# wiz16b8m4ct3_0_WIZ16B8M4CT3 register map
Vendor: Texas Instruments
Registers are 32-bit, read-write, reset 0x0 unless marked. A register's access mark holds for its fields unless they carry their own. Offsets are as the file gives them; [hi:lo] are bit positions.

## wiz16b8m4ct3_0_WIZ16B8M4CT3 (part 10 of 12)
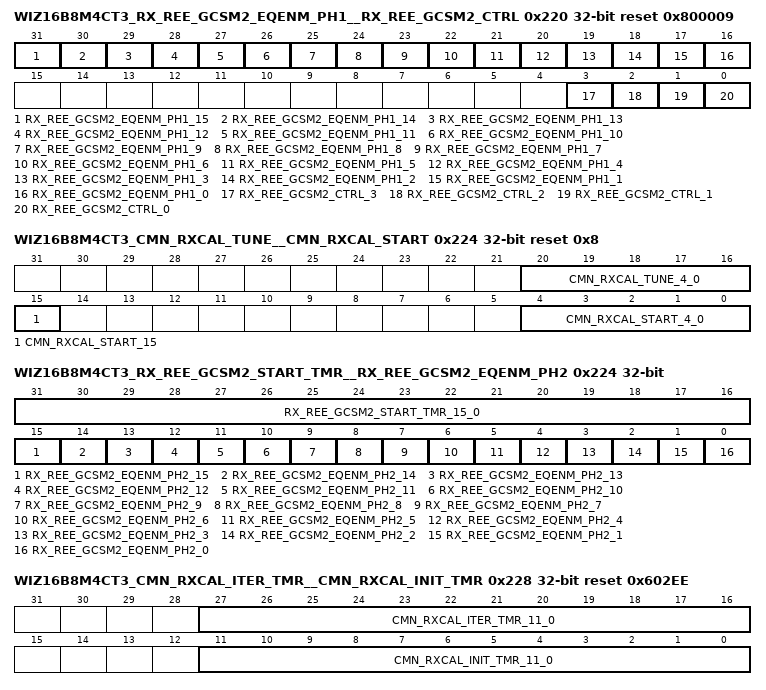
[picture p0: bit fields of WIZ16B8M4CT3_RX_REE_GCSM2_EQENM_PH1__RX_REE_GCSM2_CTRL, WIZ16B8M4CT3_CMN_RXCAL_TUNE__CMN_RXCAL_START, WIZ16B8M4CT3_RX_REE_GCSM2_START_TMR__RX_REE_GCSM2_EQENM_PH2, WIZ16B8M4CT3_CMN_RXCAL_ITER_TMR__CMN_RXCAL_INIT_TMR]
0x220 WIZ16B8M4CT3_RX_REE_GCSM2_EQENM_PH1__RX_REE_GCSM2_CTRL reset 0x800009
  [31] RX_REE_GCSM2_EQENM_PH1_15 — Reserved - spare
  [30] RX_REE_GCSM2_EQENM_PH1_14 — Ignore 1010 controller : When set to 1'b1, this function is enabled when the general control state machine 2 is controlling the REE.
  [29] RX_REE_GCSM2_EQENM_PH1_13 — TX equalization evaluator : When set to 1'b1, this function is enabled when the general control state machine 2 is controlling the REE.
  [28] RX_REE_GCSM2_EQENM_PH1_12 — TX post cursor control : When set to 1'b1, this function is enabled when the general control state machine 2 is controlling the REE.
  [27] RX_REE_GCSM2_EQENM_PH1_11 — TX pre cursor control : When set to 1'b1, this function is enabled when the general control state machine 2 is controlling the REE.
  [26] RX_REE_GCSM2_EQENM_PH1_10 — Short channel correction : When set to 1'b1, this function is enabled when the general control state machine 2 is controlling the REE.
  [25] RX_REE_GCSM2_EQENM_PH1_9 — RX attenuation : When set to 1'b1, this function is enabled when the general control state machine 2 is controlling the REE.
  [24] RX_REE_GCSM2_EQENM_PH1_8 — RX VGA gain : When set to 1'b1, this function is enabled when the general control state machine 2 is controlling the REE.
  [23] RX_REE_GCSM2_EQENM_PH1_7 — RX offset correction coefficient : When set to 1'b1, this function is enabled when the general control state machine 2 is controlling the REE.
  [22] RX_REE_GCSM2_EQENM_PH1_6 — RX peaking amp gain : When set to 1'b1, this function is enabled when the general control state machine 2 is controlling the REE.
  [21] RX_REE_GCSM2_EQENM_PH1_5 — RX low frequency equalizer adaptive control : When set to 1'b1, this function is enabled when the general control state machine 2 is controlling the REE.
  [20] RX_REE_GCSM2_EQENM_PH1_4 — Reserved - spare
  [19] RX_REE_GCSM2_EQENM_PH1_3 — Reserved - spare
  [18] RX_REE_GCSM2_EQENM_PH1_2 — RX tap 3 : When set to 1'b1, this function is enabled when the general control state machine 2 is controlling the REE.
  [17] RX_REE_GCSM2_EQENM_PH1_1 — RX tap 2 : When set to 1'b1, this function is enabled when the general control state machine 2 is controlling the REE.
  [16] RX_REE_GCSM2_EQENM_PH1_0 — RX tap 1 : When set to 1'b1, this function is enabled when the general control state machine 2 is controlling the REE.
  [3] RX_REE_GCSM2_CTRL_3 — Equalization function reset enable: Enables the reset of the functions controlled by this state machine, using the rx_ree_fcn_reset_n signal, when the equalization mode changes. 1'b1 : Enabled 1'b0 : Disabled
  [2] RX_REE_GCSM2_CTRL_2 — Loop enable: Controls when the equalization functions in this state machine are run one time or loop continuously.
  [1] RX_REE_GCSM2_CTRL_1 — Force run equalization: Setting this bit to a 1'b1, will force the general control state machine to run, independent of the macro functions that normally run the equalization.
  [0] RX_REE_GCSM2_CTRL_0 — Enable: This bit enables the general control state machine function. 1'b1 : Enabled 1'b0 : Disabled
0x224 WIZ16B8M4CT3_CMN_RXCAL_TUNE__CMN_RXCAL_START reset 0x8
  [20:16] CMN_RXCAL_TUNE_4_0 — Resistor calibration tune value: The value of this field is added to the automatically calibrated code, or the override code if override is enabled. Note: This value is a twos complement value, so the calibrated code can be increased or decreased.
  [15] CMN_RXCAL_START_15 — Resistor calibration direction: This controls the direction that the automatic calibration process steps the calibration codes in. 1'b0 : From 4'b0000 to 4'b0111. 1'b1 : From 4'b0111 to 4'b0000.
  [4:0] CMN_RXCAL_START_4_0 — Start resistor calibration code: This is the calibration code that the resistor calibration process starts with when automatic calibration is run. The following are the values for the code. 5'b00000: No resistors active 5'b00001: 1 resistor active 5'b00010: 2 resistors active 5'b00011: 3 resistors active ... 5'b01110: 14 resistors active. 5'b01111: 15 resistors active. Note: The most significant bit is the calibration code sign bit, and is always 1'b0 in this application.
0x224 WIZ16B8M4CT3_RX_REE_GCSM2_START_TMR__RX_REE_GCSM2_EQENM_PH2
  [31:16] RX_REE_GCSM2_START_TMR_15_0 — Start timer value : The number of clock cycles the state machine will wait in the Start Delay state. Note: This value is shifted left 8 bits when loading the timer, the actual time is 256X this value.
  [15] RX_REE_GCSM2_EQENM_PH2_15 — Reserved - spare
  [14] RX_REE_GCSM2_EQENM_PH2_14 — Ignore 1010 controller : When set to 1'b1, this function is enabled when the general control state machine 2 is controlling the REE.
  [13] RX_REE_GCSM2_EQENM_PH2_13 — TX equalization evaluator : When set to 1'b1, this function is enabled when the general control state machine 2 is controlling the REE.
  [12] RX_REE_GCSM2_EQENM_PH2_12 — TX post cursor control : When set to 1'b1, this function is enabled when the general control state machine 2 is controlling the REE.
  [11] RX_REE_GCSM2_EQENM_PH2_11 — TX pre cursor control : When set to 1'b1, this function is enabled when the general control state machine 2 is controlling the REE.
  [10] RX_REE_GCSM2_EQENM_PH2_10 — Short channel correction : When set to 1'b1, this function is enabled when the general control state machine 2 is controlling the REE.
  [9] RX_REE_GCSM2_EQENM_PH2_9 — RX attenuation : When set to 1'b1, this function is enabled when the general control state machine 2 is controlling the REE.
  [8] RX_REE_GCSM2_EQENM_PH2_8 — RX VGA gain : When set to 1'b1, this function is enabled when the general control state machine 2 is controlling the REE.
  [7] RX_REE_GCSM2_EQENM_PH2_7 — RX offset correction coefficient : When set to 1'b1, this function is enabled when the general control state machine 2 is controlling the REE.
  [6] RX_REE_GCSM2_EQENM_PH2_6 — RX peaking amp gain : When set to 1'b1, this function is enabled when the general control state machine 2 is controlling the REE.
  [5] RX_REE_GCSM2_EQENM_PH2_5 — RX low frequency equalizer adaptive control : When set to 1'b1, this function is enabled when the general control state machine 2 is controlling the REE.
  [4] RX_REE_GCSM2_EQENM_PH2_4 — Reserved - spare
  [3] RX_REE_GCSM2_EQENM_PH2_3 — Reserved - spare
  [2] RX_REE_GCSM2_EQENM_PH2_2 — RX tap 3 : When set to 1'b1, this function is enabled when the general control state machine 2 is controlling the REE.
  [1] RX_REE_GCSM2_EQENM_PH2_1 — RX tap 2 : When set to 1'b1, this function is enabled when the general control state machine 2 is controlling the REE.
  [0] RX_REE_GCSM2_EQENM_PH2_0 — RX tap 1 : When set to 1'b1, this function is enabled when the general control state machine 2 is controlling the REE.
0x228 WIZ16B8M4CT3_CMN_RXCAL_ITER_TMR__CMN_RXCAL_INIT_TMR reset 0x602EE
  [27:16] CMN_RXCAL_ITER_TMR_11_0 — Iteration wait timer value: This is the number of cmn_ref_clk clocks to wait between when a value is placed on the resistor selection bus going to the analog, and when the comparator value coming from the analog circuits can be checked. Note: This results in the minimum number of cmn_ref_clk clocks required to wait 240 nSec. Note: This should never be set to a value of less than 3.
  [11:0] CMN_RXCAL_INIT_TMR_11_0 — Initialization wait timer value: This is the number of cmn_ref_clk clocks to wait between when the analog resistor calibration circuits are enabled, and when the first resistor selection values are placed on the resistor selection bus, going to the analog. Note: This results in the minimum number of cmn_ref_clk clocks required to wait 30 uSec. Note: This should never be set to a value of less than 1.
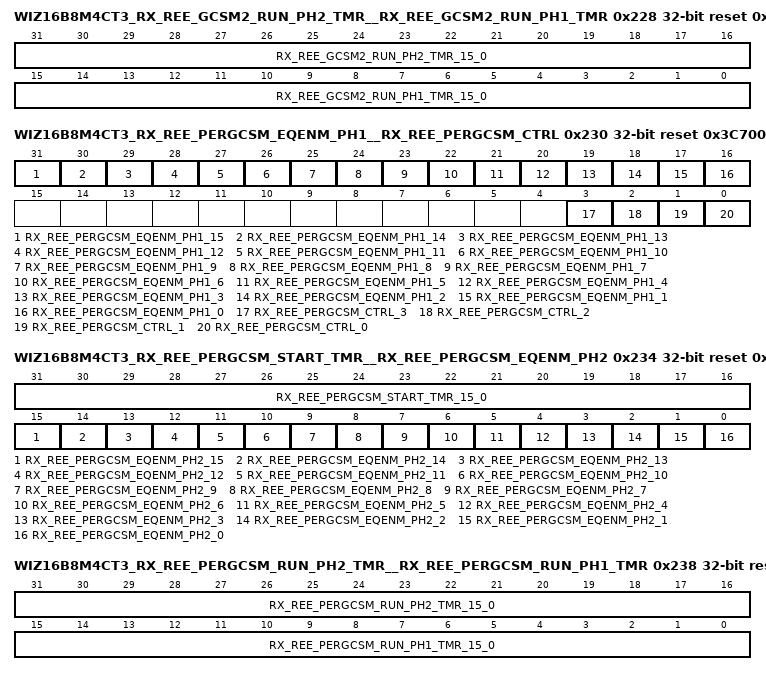
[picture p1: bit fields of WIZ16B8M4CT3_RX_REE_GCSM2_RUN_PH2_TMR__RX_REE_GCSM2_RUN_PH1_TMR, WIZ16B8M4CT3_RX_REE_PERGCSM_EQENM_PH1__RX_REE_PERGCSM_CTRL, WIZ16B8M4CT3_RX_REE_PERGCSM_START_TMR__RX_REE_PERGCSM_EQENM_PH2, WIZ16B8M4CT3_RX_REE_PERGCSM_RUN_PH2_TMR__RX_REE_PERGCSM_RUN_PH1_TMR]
0x228 WIZ16B8M4CT3_RX_REE_GCSM2_RUN_PH2_TMR__RX_REE_GCSM2_RUN_PH1_TMR reset 0xFFFF
  [31:16] RX_REE_GCSM2_RUN_PH2_TMR_15_0 — Run phase 2 timer value : This specifies the number of clock cycles the state machine will wait in the Run Equalization Phase 2 state. Note: This value is shifted left 8 bits when loading the timer, the actual time is 256X this value.
  [15:0] RX_REE_GCSM2_RUN_PH1_TMR_15_0 — Run phase 1 timer value : This specifies the number of clock cycles the state machine will wait in the Run Equalization Phase 1 state. If this register is set to all 1s, the run in the Run Equalization Phase 1 state indefinitely. Note: This value is shifted left 8 bits when loading the timer, the actual time is 256X this value.
0x230 WIZ16B8M4CT3_RX_REE_PERGCSM_EQENM_PH1__RX_REE_PERGCSM_CTRL reset 0x3C7000D
  [31] RX_REE_PERGCSM_EQENM_PH1_15 — Reserved - spare
  [30] RX_REE_PERGCSM_EQENM_PH1_14 — Ignore 1010 controller : When set to 1'b1, this function is enabled when the periodic general control state machine is controlling the REE.
  [29] RX_REE_PERGCSM_EQENM_PH1_13 — TX equalization evaluator : When set to 1'b1, this function is enabled when the periodic general control state machine is controlling the REE.
  [28] RX_REE_PERGCSM_EQENM_PH1_12 — TX post cursor control : When set to 1'b1, this function is enabled when the periodic general control state machine is controlling the REE.
  [27] RX_REE_PERGCSM_EQENM_PH1_11 — TX pre cursor control : When set to 1'b1, this function is enabled when the periodic general control state machine is controlling the REE.
  [26] RX_REE_PERGCSM_EQENM_PH1_10 — Short channel correction : When set to 1'b1, this function is enabled when the periodic general control state machine is controlling the REE.
  [25] RX_REE_PERGCSM_EQENM_PH1_9 — RX attenuation : When set to 1'b1, this function is enabled when the periodic general control state machine is controlling the REE.
  [24] RX_REE_PERGCSM_EQENM_PH1_8 — RX VGA gain : When set to 1'b1, this function is enabled when the periodic general control state machine is controlling the REE.
  [23] RX_REE_PERGCSM_EQENM_PH1_7 — RX offset correction coefficient : When set to 1'b1, this function is enabled when the periodic general control state machine is controlling the REE.
  [22] RX_REE_PERGCSM_EQENM_PH1_6 — RX peaking amp gain : When set to 1'b1, this function is enabled when the periodic general control state machine is controlling the REE.
  [21] RX_REE_PERGCSM_EQENM_PH1_5 — RX low frequency equalizer adaptive control : When set to 1'b1, this function is enabled when the periodic general control state machine is controlling the REE.
  [20] RX_REE_PERGCSM_EQENM_PH1_4 — Reserved - spare
  [19] RX_REE_PERGCSM_EQENM_PH1_3 — Reserved - spare
  [18] RX_REE_PERGCSM_EQENM_PH1_2 — RX tap 3 : When set to 1'b1, this function is enabled when the periodic general control state machine is controlling the REE.
  [17] RX_REE_PERGCSM_EQENM_PH1_1 — RX tap 2 : When set to 1'b1, this function is enabled when the periodic general control state machine is controlling the REE.
  [16] RX_REE_PERGCSM_EQENM_PH1_0 — RX tap 1 : When set to 1'b1, this function is enabled when the periodic general control state machine is controlling the REE.
  [3] RX_REE_PERGCSM_CTRL_3 — Equalization function reset enable: Enables the reset of the functions controlled by this state machine, using the rx_ree_fcn_reset_n pin, when the equalization mode changes. 1'b1 : Enabled 1'b0 : Disabled
  [2] RX_REE_PERGCSM_CTRL_2 — Loop enable: Controls when the equalization functions in this state machine are run one time or loop continuously.
  [1] RX_REE_PERGCSM_CTRL_1 — Force run equalization: Setting this bit to a 1'b1, will force the general control state machine to run, independent of the macro functions that normally run the equalization.
  [0] RX_REE_PERGCSM_CTRL_0 — Enable: This bit enables the general control state machine function. 1'b1 : Enabled 1'b0 : Disabled
0x234 WIZ16B8M4CT3_RX_REE_PERGCSM_START_TMR__RX_REE_PERGCSM_EQENM_PH2 reset 0x1E8501C7
  [31:16] RX_REE_PERGCSM_START_TMR_15_0 — Start timer value : The number of clock cycles the state machine will wait in the Start Delay state. Note: This value is shifted left 8 bits when loading the timer, the actual time is 256X this value.
  [15] RX_REE_PERGCSM_EQENM_PH2_15 — Reserved - spare
  [14] RX_REE_PERGCSM_EQENM_PH2_14 — Ignore 1010 controller : When set to 1'b1, this function is enabled when the periodic general control state machine is controlling the REE.
  [13] RX_REE_PERGCSM_EQENM_PH2_13 — TX equalization evaluator : When set to 1'b1, this function is enabled when the periodic general control state machine is controlling the REE.
  [12] RX_REE_PERGCSM_EQENM_PH2_12 — TX post cursor control : When set to 1'b1, this function is enabled when the periodic general control state machine is controlling the REE.
  [11] RX_REE_PERGCSM_EQENM_PH2_11 — TX pre cursor control : When set to 1'b1, this function is enabled when the periodic general control state machine is controlling the REE.
  [10] RX_REE_PERGCSM_EQENM_PH2_10 — Short channel correction : When set to 1'b1, this function is enabled when the periodic general control state machine is controlling the REE.
  [9] RX_REE_PERGCSM_EQENM_PH2_9 — RX attenuation : When set to 1'b1, this function is enabled when the periodic general control state machine is controlling the REE.
  [8] RX_REE_PERGCSM_EQENM_PH2_8 — RX VGA gain : When set to 1'b1, this function is enabled when the periodic general control state machine is controlling the REE.
  [7] RX_REE_PERGCSM_EQENM_PH2_7 — RX offset correction coefficient : When set to 1'b1, this function is enabled when the periodic general control state machine is controlling the REE.
  [6] RX_REE_PERGCSM_EQENM_PH2_6 — RX peaking amp gain : When set to 1'b1, this function is enabled when the periodic general control state machine is controlling the REE.
  [5] RX_REE_PERGCSM_EQENM_PH2_5 — RX low frequency equalizer adaptive control : When set to 1'b1, this function is enabled when the periodic general control state machine is controlling the REE.
  [4] RX_REE_PERGCSM_EQENM_PH2_4 — Reserved - spare
  [3] RX_REE_PERGCSM_EQENM_PH2_3 — Reserved - spare
  [2] RX_REE_PERGCSM_EQENM_PH2_2 — RX tap 3 : When set to 1'b1, this function is enabled when the periodic general control state machine is controlling the REE.
  [1] RX_REE_PERGCSM_EQENM_PH2_1 — RX tap 2 : When set to 1'b1, this function is enabled when the periodic general control state machine is controlling the REE.
  [0] RX_REE_PERGCSM_EQENM_PH2_0 — RX tap 1 : When set to 1'b1, this function is enabled when the periodic general control state machine is controlling the REE.
0x238 WIZ16B8M4CT3_RX_REE_PERGCSM_RUN_PH2_TMR__RX_REE_PERGCSM_RUN_PH1_TMR reset 0x9D009D
  [31:16] RX_REE_PERGCSM_RUN_PH2_TMR_15_0 — Run phase 2 timer value : This specifies the number of clock cycles the state machine will wait in the Run Equalization Phase 2 state. Note: This value is shifted left 8 bits when loading the timer, the actual time is 256X this value.
  [15:0] RX_REE_PERGCSM_RUN_PH1_TMR_15_0 — Run phase 1 timer value : This specifies the number of clock cycles the state machine will wait in the Run Equalization Phase 1 state. If this register is set to all 1s, the run in the Run Equalization Phase 1 state indefinitely. Note: This value is shifted left 8 bits when loading the timer, the actual time is 256X this value.
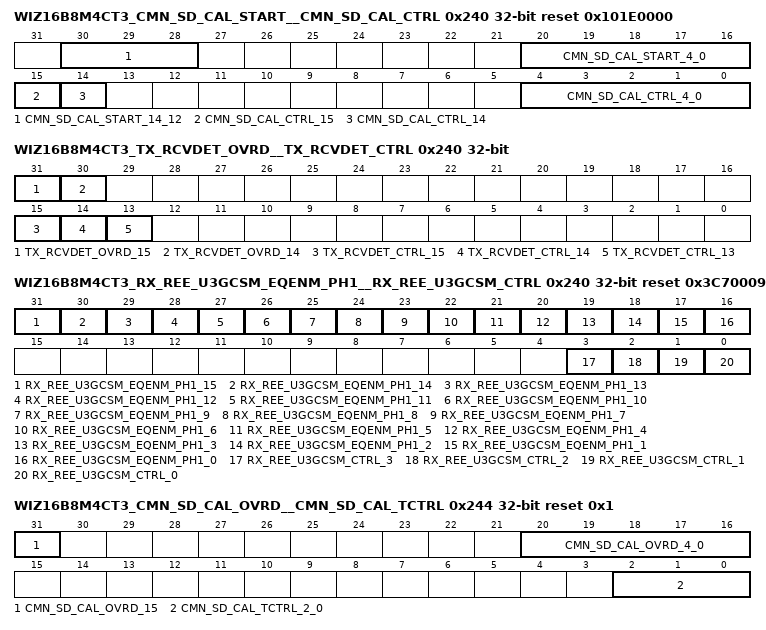
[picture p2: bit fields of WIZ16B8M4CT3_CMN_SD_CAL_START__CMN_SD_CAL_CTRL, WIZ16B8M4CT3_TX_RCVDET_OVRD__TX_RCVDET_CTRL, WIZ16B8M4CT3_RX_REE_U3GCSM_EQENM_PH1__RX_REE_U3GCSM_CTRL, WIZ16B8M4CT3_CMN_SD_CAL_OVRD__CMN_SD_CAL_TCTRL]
0x240 WIZ16B8M4CT3_CMN_SD_CAL_START__CMN_SD_CAL_CTRL access per field reset 0x101E0000
  [30:28] CMN_SD_CAL_START_14_12 rw — Calibration initial step size control: This field specifies the initial step size for the calibration state machine. The following are the values that can be used in this field, and the corresponding step sizes. 3'b000 : 1 3'b001 : 2 3'b010 : 4 3'b011 : 8 3'b100 : 16 3'b101 - 3'b111 : Reserved
  [20:16] CMN_SD_CAL_START_4_0 rw — Calibration code starting point value: This field specifies the starting code that is used by the calibration state machine. The purpose of this value is such that the calibration process starts at a point that is, on average, relatively close to the final calibration point. This allows the calibration time to be reduced, on average. The following are the values for this code: 5'b00000: 0 Capacitors activated 5'b00001: 1 Capacitor activated 5'b00010: 2 Capacitors activated 5'b00011: 3 Capacitors activated ... 5'b11110: 30 Capacitors activated 5'b11111: 31 Capacitors activated Note: This field is intended to be for diagnostics purposes only. Note : This field must be set to a value that is always at least one step size away from the minimum and maximum calibration codes, and is a function of the step size specified in this register. For example, if the initial step size is 4, this value must be at least 4 greater than the minimum calibration code or 4 less than the maximum calibration code. Note: The reset value for this field is with the common calibration power island switched off. In cases where this power island is switched on, the reset value be 5'b11110
  [15] CMN_SD_CAL_CTRL_15 rw — Start calibration: Activating (1'b1) this bit will start a calibration process. This bit must remain active until the calibration process is complete (as indicated by the calibration process done bit in this register). To start another calibration process, the calibration process done bit must have gone inactive from any prior calibration process. Note: This bit is intended to be for diagnostics purposes only. This calibration process is automatically activated internally by the startup state machine. When using this bit, the user must wait until after the internally activated process completes.
  [14] CMN_SD_CAL_CTRL_14 ro — Calibration process done: This bit will be set to 1'b1 when the calibration process is complete. It will be cleared by the deactivation of the Start calibration bit in this register. Note: This bit is intended to be for diagnostics purposes only. Note: This bit is not likely to be observed as being set after internal automatic calibration is complete, because the internally generated run signal will be driven inactive immediately after the done signal is activated, and therefore the internal done signal will be cleared.
  [4:0] CMN_SD_CAL_CTRL_4_0 ro — Calibration code: This is the calibration code that was determined by the calibration process. This signal is valid when the calibration process is complete. The values of this field correspond to different frequency bands the will operate in. The frequency bands are controlled by the number of capacitors that are switched in the analog circuit. This field specifies the number of capacitors that are switched in. The following are the values for this code: 5'b00000: 0 Capacitors activated 5'b00001: 1 Capacitor activated 5'b00010: 2 Capacitors activated 5'b00011: 3 Capacitors activated ... 5'b11110: 30 Capacitors activated 5'b11111: 31 Capacitors activated Note: This signal is intended to be for diagnostics purposes only. Note: The reset value for this field is with the common calibration power island switched off. In cases where this power island is switched on, the reset value be 5'b11110
0x240 WIZ16B8M4CT3_TX_RCVDET_OVRD__TX_RCVDET_CTRL access per field
  [31] TX_RCVDET_OVRD_15 rw — Receiver detect override enable: Activation (1'b1) of this register bit enables the tx_rcv_detected output from the receiver detect state machine to be driven directly by the receiver detect override bit in this register.
  [30] TX_RCVDET_OVRD_14 rw — Receiver detect override: When the receiver detect override enable bit in this register is active (1'b1), this bit will directly control the tx_rcv_detected output from the receiver detect state machine.
  [15] TX_RCVDET_CTRL_15 rw — Start receiver detect: Activating (1'b1) this bit will start the receiver detect process. This bit must remain active until the receiver detect process is complete, as indicated by the receiver detect process done bit in this register. To start another receiver detect process, this register must first be set inactive (1'b0) until the receiver detect process done bit in this register is cleared. Note: This bit is intended to be for diagnostics purposes only. The receiver detect process must not be under the control of the top level tx_rcv_detect_en pin when attempting to initiate the process using this register.
  [14] TX_RCVDET_CTRL_14 ro — Receiver detect process done: This bit will be set to 1'b1 when the receiver detect process is complete. It will be cleared by cmn_reset_n, or by the deactivation of the start receiver detect bit in this register. Note: This bit is intended to be for diagnostics purposes only.
  [13] TX_RCVDET_CTRL_13 ro — Receiver detected: When the receiver detect process is complete, this register bit will indicate the current state of the tx_rcv_detected pin.
0x240 WIZ16B8M4CT3_RX_REE_U3GCSM_EQENM_PH1__RX_REE_U3GCSM_CTRL reset 0x3C70009
  [31] RX_REE_U3GCSM_EQENM_PH1_15 — Reserved - spare
  [30] RX_REE_U3GCSM_EQENM_PH1_14 — Ignore 1010 controller : When set to 1'b1, this function is enabled when the USB 3.0 general control state machine is controlling the REE.
  [29] RX_REE_U3GCSM_EQENM_PH1_13 — TX equalization evaluator : When set to 1'b1, this function is enabled when the USB 3.0 general control state machine is controlling the REE.
  [28] RX_REE_U3GCSM_EQENM_PH1_12 — TX post cursor control : When set to 1'b1, this function is enabled when the USB 3.0 general control state machine is controlling the REE.
  [27] RX_REE_U3GCSM_EQENM_PH1_11 — TX pre cursor control : When set to 1'b1, this function is enabled when the USB 3.0 general control state machine is controlling the REE.
  [26] RX_REE_U3GCSM_EQENM_PH1_10 — Short channel correction : When set to 1'b1, this function is enabled when the USB 3.0 general control state machine is controlling the REE.
  [25] RX_REE_U3GCSM_EQENM_PH1_9 — RX attenuation : When set to 1'b1, this function is enabled when the USB 3.0 general control state machine is controlling the REE.
  [24] RX_REE_U3GCSM_EQENM_PH1_8 — RX VGA gain : When set to 1'b1, this function is enabled when the USB 3.0 general control state machine is controlling the REE.
  [23] RX_REE_U3GCSM_EQENM_PH1_7 — RX offset correction coefficient : When set to 1'b1, this function is enabled when the USB 3.0 general control state machine is controlling the REE.
  [22] RX_REE_U3GCSM_EQENM_PH1_6 — RX peaking amp gain : When set to 1'b1, this function is enabled when the USB 3.0 general control state machine is controlling the REE.
  [21] RX_REE_U3GCSM_EQENM_PH1_5 — RX low frequency equalizer adaptive control : When set to 1'b1, this function is enabled when the USB 3.0 general control state machine is controlling the REE.
  [20] RX_REE_U3GCSM_EQENM_PH1_4 — Reserved - spare
  [19] RX_REE_U3GCSM_EQENM_PH1_3 — Reserved - spare
  [18] RX_REE_U3GCSM_EQENM_PH1_2 — RX tap 3 : When set to 1'b1, this function is enabled when the USB 3.0 general control state machine is controlling the REE.
  [17] RX_REE_U3GCSM_EQENM_PH1_1 — RX tap 2 : When set to 1'b1, this function is enabled when the USB 3.0 general control state machine is controlling the REE.
  [16] RX_REE_U3GCSM_EQENM_PH1_0 — RX tap 1 : When set to 1'b1, this function is enabled when the USB 3.0 general control state machine is controlling the REE.
  [3] RX_REE_U3GCSM_CTRL_3 — Equalization function reset enable: Enables the reset of the functions controlled by this state machine, using the rx_ree_fcn_reset_n pin, when the equalization mode changes. 1'b1 : Enabled 1'b0 : Disabled
  [2] RX_REE_U3GCSM_CTRL_2 — Loop enable: Controls when the equalization functions in this state machine are run one time or loop continuously.
  [1] RX_REE_U3GCSM_CTRL_1 — Force run equalization: Setting this bit to a 1'b1, will force the general control state machine to run, independent of the macro functions that normally run the equalization.
  [0] RX_REE_U3GCSM_CTRL_0 — Enable: This bit enables the general control state machine function. 1'b1 : Enabled 1'b0 : Disabled
0x244 WIZ16B8M4CT3_CMN_SD_CAL_OVRD__CMN_SD_CAL_TCTRL reset 0x1
  [31] CMN_SD_CAL_OVRD_15 — Calibration code override enable: Activating (1'b1) this bit allows the code determined during the automatic calibration process to be overridden by the value driven by the calibration code override value field in this register. Note: This bit is intended to be for diagnostics purposes only. Note: This bit should not be activated while a calibration is currently in progress.
  [20:16] CMN_SD_CAL_OVRD_4_0 — Calibration code override value: This field is used to override the code determined during the automatic calibration process. The code driven on this field is valid when the calibration code override enable bit in this register is active. The following are the values for this code: 5'b00000: 0 Capacitors activated 5'b00001: 1 Capacitor activated 5'b00010: 2 Capacitors activated 5'b00011: 3 Capacitors activated ... 5'b11110: 30 Capacitors activated 5'b11111: 31 Capacitors activated Note: This field is intended to be for diagnostics purposes only. Note: The value of this field must not be changed while the calibration function is running.
  [2:0] CMN_SD_CAL_TCTRL_2_0 — Calibration initial time scale control: This field specifies the calibration start time scaling factor applied to the calibration when running the initial step size for the calibration code is not set to 1. Setting this value to a value other than 1 will reduce the calibration measurement time by the amount specified below. Then when the final calibration steps are made the full calibration time will be used to get the appropriate amount of resolution. 3'b000 : Div 1 3'b001 : Div 2 3'b010 : Div 4 3'b011 : Div 8 3'b100 : Div 16 3'b101 : Div 32 3'b110 : Div 64 3'b111 : Div 128
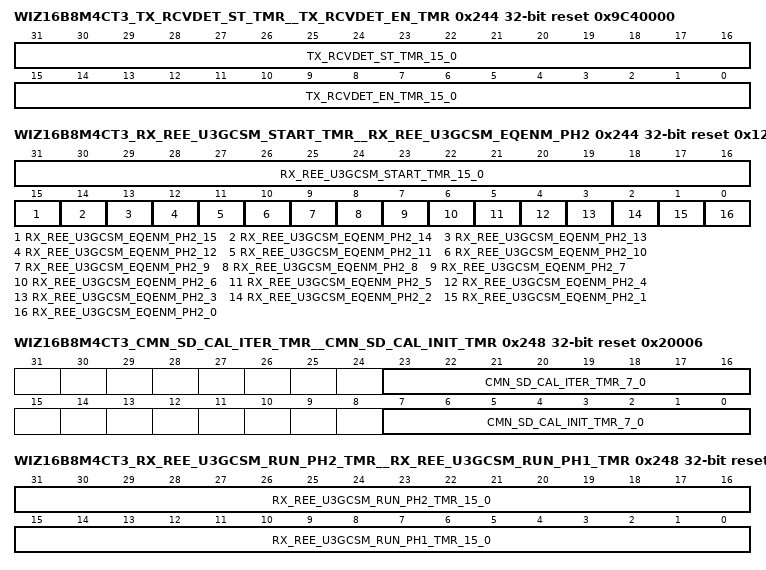
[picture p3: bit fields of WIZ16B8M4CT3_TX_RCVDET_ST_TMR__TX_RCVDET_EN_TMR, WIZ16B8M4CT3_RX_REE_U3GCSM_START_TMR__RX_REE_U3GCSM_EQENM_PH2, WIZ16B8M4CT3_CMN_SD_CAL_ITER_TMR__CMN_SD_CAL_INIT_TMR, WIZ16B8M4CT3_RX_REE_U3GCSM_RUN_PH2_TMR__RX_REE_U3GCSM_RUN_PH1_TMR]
0x244 WIZ16B8M4CT3_TX_RCVDET_ST_TMR__TX_RCVDET_EN_TMR reset 0x9C40000
  [31:16] TX_RCVDET_ST_TMR_15_0 — Start wait time value: This is the number of clocks the receiver detect state machine waits between driving the txda_rcvdet_start signal active and checking the results on the txda_rcvdet_detected_n signal coming from the analog. The default required wait time is 100us.
  [15:0] TX_RCVDET_EN_TMR_15_0 — Enable wait time value: This is the number of clocks the receiver detect state machine waits between driving the txda_rcvdet_en signal active and driving the txda_rcvdet_start signal active going to the analog.
0x244 WIZ16B8M4CT3_RX_REE_U3GCSM_START_TMR__RX_REE_U3GCSM_EQENM_PH2 reset 0x12501C7
  [31:16] RX_REE_U3GCSM_START_TMR_15_0 — Start timer value : The number of clock cycles the state machine will wait in the Start Delay state. Note: This value is shifted left 8 bits when loading the timer, the actual time is 256X this value.
  [15] RX_REE_U3GCSM_EQENM_PH2_15 — Reserved - spare
  [14] RX_REE_U3GCSM_EQENM_PH2_14 — Ignore 1010 controller : When set to 1'b1, this function is enabled when the USB 3.0 general control state machine is controlling the REE.
  [13] RX_REE_U3GCSM_EQENM_PH2_13 — TX equalization evaluator : When set to 1'b1, this function is enabled when the USB 3.0 general control state machine is controlling the REE.
  [12] RX_REE_U3GCSM_EQENM_PH2_12 — TX post cursor control : When set to 1'b1, this function is enabled when the USB 3.0 general control state machine is controlling the REE.
  [11] RX_REE_U3GCSM_EQENM_PH2_11 — TX pre cursor control : When set to 1'b1, this function is enabled when the USB 3.0 general control state machine is controlling the REE.
  [10] RX_REE_U3GCSM_EQENM_PH2_10 — Short channel correction : When set to 1'b1, this function is enabled when the USB 3.0 general control state machine is controlling the REE.
  [9] RX_REE_U3GCSM_EQENM_PH2_9 — RX attenuation : When set to 1'b1, this function is enabled when the USB 3.0 general control state machine is controlling the REE.
  [8] RX_REE_U3GCSM_EQENM_PH2_8 — RX VGA gain : When set to 1'b1, this function is enabled when the USB 3.0 general control state machine is controlling the REE.
  [7] RX_REE_U3GCSM_EQENM_PH2_7 — RX offset correction coefficient : When set to 1'b1, this function is enabled when the USB 3.0 general control state machine is controlling the REE.
  [6] RX_REE_U3GCSM_EQENM_PH2_6 — RX peaking amp gain : When set to 1'b1, this function is enabled when the USB 3.0 general control state machine is controlling the REE.
  [5] RX_REE_U3GCSM_EQENM_PH2_5 — RX low frequency equalizer adaptive control : When set to 1'b1, this function is enabled when the USB 3.0 general control state machine is controlling the REE.
  [4] RX_REE_U3GCSM_EQENM_PH2_4 — Reserved - spare
  [3] RX_REE_U3GCSM_EQENM_PH2_3 — Reserved - spare
  [2] RX_REE_U3GCSM_EQENM_PH2_2 — RX tap 3 : When set to 1'b1, this function is enabled when the USB 3.0 general control state machine is controlling the REE.
  [1] RX_REE_U3GCSM_EQENM_PH2_1 — RX tap 2 : When set to 1'b1, this function is enabled when the USB 3.0 general control state machine is controlling the REE.
  [0] RX_REE_U3GCSM_EQENM_PH2_0 — RX tap 1 : When set to 1'b1, this function is enabled when the USB 3.0 general control state machine is controlling the REE.
0x248 WIZ16B8M4CT3_CMN_SD_CAL_ITER_TMR__CMN_SD_CAL_INIT_TMR reset 0x20006
  [23:16] CMN_SD_CAL_ITER_TMR_7_0 — Iteration wait timer value: This is the number of clocks to wait between when a calibration code is driven to the analog, and when the clock rates are measured. Note: This results in the minimum number of cmn_ref_clk clocks required to wait 80 nSec.
  [7:0] CMN_SD_CAL_INIT_TMR_7_0 — Initialization wait timer value: This is the number of clocks to wait between when the analog calibration circuits are enabled, and when the first calibration code is driven to the analog. Note: This results in the minimum number of cmn_ref_clk clocks required to wait 80 nSec for the analog plus four reference clocks for the digital clock gating to be enabled.
0x248 WIZ16B8M4CT3_RX_REE_U3GCSM_RUN_PH2_TMR__RX_REE_U3GCSM_RUN_PH1_TMR reset 0x9D07A2
  [31:16] RX_REE_U3GCSM_RUN_PH2_TMR_15_0 — Run phase 2 timer value : This specifies the number of clock cycles the state machine will wait in the Run Equalization Phase 2 state. Note: This value is shifted left 8 bits when loading the timer, the actual time is 256X this value.
  [15:0] RX_REE_U3GCSM_RUN_PH1_TMR_15_0 — Run phase 1 timer value : This specifies the number of clock cycles the state machine will wait in the Run Equalization Phase 1 state. If this register is set to all 1s, the run in the Run Equalization Phase 1 state indefinitely. Note: This value is shifted left 8 bits when loading the timer, the actual time is 256X this value.
0x24C WIZ16B8M4CT3_CMN_SD_CAL_REFTIM_START reset 0xE
  [7:0] CMN_SD_CAL_REFTIM_START_7_0 — Calibration reference clock timer start value : This is the value that is loaded into the reference clock timer as the starting point for that timer, when running calibration. Note: The actual number of clocks counted is one larger than what is specified by this field.
0x250 WIZ16B8M4CT3_CMN_SD_CAL_PLLCNT_START reset 0x12B
  [9:0] CMN_SD_CAL_PLLCNT_START_9_0 — Calibration feedback clock counter start value : This is the value that is loaded into the PLL clock counter as the starting point for that counter, when running calibration. Note: The actual number of clocks counted is one larger than what is specified by this field.
0x250 WIZ16B8M4CT3_RX_REE_ANAENSM_DEL_TMR reset 0x64
  [15:0] RX_REE_ANAENSM_DEL_TMR_15_0 — Analog enable delay timer value : The number of clock cycles the state machine will wait in the Analog Enable Delay state. The time specified here is the number of clock cycles to wait between when the analog enable signal (ana_en) is initially driven active, until the ana_en_ack signal is driven active. The intention of this timer is to provide for the necessary amount of time between when the analog enable is driven active until when data controlled by the analog enable is considered valid.
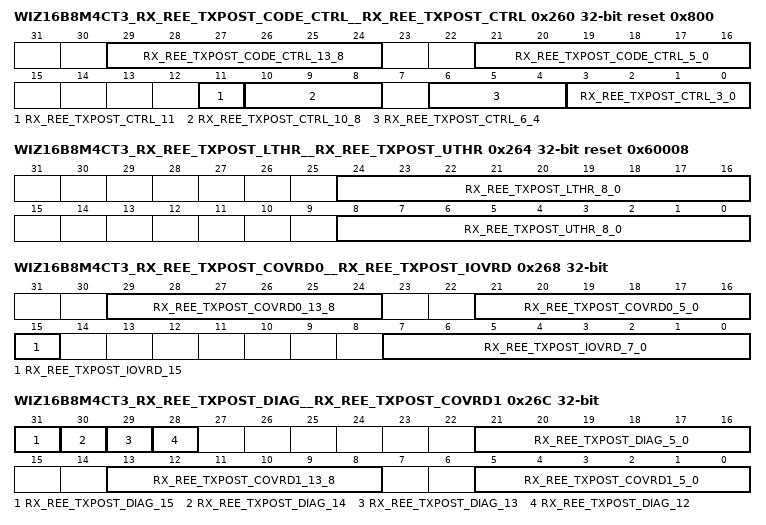
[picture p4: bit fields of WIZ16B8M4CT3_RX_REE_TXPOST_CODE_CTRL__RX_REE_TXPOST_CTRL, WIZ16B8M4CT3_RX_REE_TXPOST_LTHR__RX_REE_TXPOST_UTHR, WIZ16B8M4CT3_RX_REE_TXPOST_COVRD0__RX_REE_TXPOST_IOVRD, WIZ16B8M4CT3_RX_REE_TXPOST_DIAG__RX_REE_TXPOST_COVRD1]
0x260 WIZ16B8M4CT3_RX_REE_TXPOST_CODE_CTRL__RX_REE_TXPOST_CTRL reset 0x800
  [29:24] RX_REE_TXPOST_CODE_CTRL_13_8 — Peaking amp code maximum value: This is the maximum value that the peaking amp code will be allowed to increase to. Note: This function is unused in the TX post-cursor control.
  [21:16] RX_REE_TXPOST_CODE_CTRL_5_0 — Peaking amp initial code: Initial value the peaking amp code is set to when training starts. Note: This function is unused in the TX post-cursor control.
  [11] RX_REE_TXPOST_CTRL_11 — Peaking amp feedback path enable: Enables the peaking amp feedback path.
  [10:8] RX_REE_TXPOST_CTRL_10_8 — Peaking amp feedback scaler value: Specifies the amount to scale the peaking amp feedback by. The following are the valid settings for this signal: 3'b110 : /4 3'b111 : /2 3'b000 : x1 3'b001 : x2 3'b010 : x4
  [6:4] RX_REE_TXPOST_CTRL_6_4 — Peaking amp integrator accumulator scaler value: Specifies the amount to scale the input to the peaking amp integrator accumulator by. The following are the valid settings for this field: 3'b000: x1 3'b001: x2 3'b010: x4 3'b011: x8 3'b100: x16 3'b101 - 3'b111: Reserved Note: This function is unused in the TX post-cursor control.
  [3:0] RX_REE_TXPOST_CTRL_3_0 — Peaking amp sigma delta accumulator scaler value: Specifies the amount to scale the input to the peaking amp sigma delta accumulator by. The following are the valid settings for this field: 4'b0000: x1 4'b0001: x2 4'b0010: x4 4'b0011: x8 4'b0100: x16 4'b0101: x 32 4'b0110: x 64 4'b0111: x128 4'b1000: x256 4'b1001: x512 4'b1010: x1024 4'b1011: x2048 4'b1100: x 4096 4'b1101 x 8192 4'b1110 x 16384 4'b1111 x 32768
0x264 WIZ16B8M4CT3_RX_REE_TXPOST_LTHR__RX_REE_TXPOST_UTHR reset 0x60008
  [24:16] RX_REE_TXPOST_LTHR_8_0 — Peaking amp algorithm lower threshold: This is the lower threshold value used in the peaking amp algorithm.
  [8:0] RX_REE_TXPOST_UTHR_8_0 — Peaking amp algorithm upper threshold: This is the upper threshold value used in the peaking amp algorithm.
0x268 WIZ16B8M4CT3_RX_REE_TXPOST_COVRD0__RX_REE_TXPOST_IOVRD
  [29:24] RX_REE_TXPOST_COVRD0_13_8 — Peaking amp code override value mode 1: Value that will override the peaking amp code when in standard mode 1 when the peaking amp code override enable bit in the REE TX post cursor diagnostics register (!) on page 270 is active.
  [21:16] RX_REE_TXPOST_COVRD0_5_0 — Peaking amp code override value mode 0: Value that will override the peaking amp code when in standard mode 0 when the peaking amp code override enable bit in the REE TX post cursor diagnostics register (!) on page 270 is active.
  [15] RX_REE_TXPOST_IOVRD_15 — Peaking amp tap accumulator input override enable: Setting this bit to a 1'b1 will allow the tap accumulator input in the peaking amp gain algorithm to be overridden by the peaking amp tap accumulator input override field in this register. Note: This function is unused in the TX post-cursor control.
  [7:0] RX_REE_TXPOST_IOVRD_7_0 — Peaking amp tap accumulator input override : Value that will override the tap accumulator input in the peaking amp gain algorithm, when the Peaking amp tap accumulator input override enable bit is active. Note: This function is unused in the TX post-cursor control.
0x26C WIZ16B8M4CT3_RX_REE_TXPOST_DIAG__RX_REE_TXPOST_COVRD1 access per field
  [31] RX_REE_TXPOST_DIAG_15 rw — Peaking amp code override enable: Setting this bit to a 1'b1 will allow the peaking amp code to be overridden by the peaking amp code override value fields in the REE TX post cursor code override 0 register (!) on page 269 and REE TX post cursor code override 1 register (!) on page 269.
  [30] RX_REE_TXPOST_DIAG_14 rw — Voter override neg : Writing a 1'b1 in this register bit will force the peaking amp voter function to activate the voter neg signal for a single clock cycle. Note : This bit must be cleared after each time it is enabled, in order to perform follow on voter override functions with this bit. Note : It is not valid to activate both the voter override neg and voter override pos at the same time.
  [29] RX_REE_TXPOST_DIAG_13 rw — Voter override pos : Writing a 1'b1 in this register bit will force the peaking amp voter function to activate the voter pos signal for a single clock cycle. Note : This bit must be cleared after each time it is enabled, in order to perform follow on voter override functions with this bit. Note : It is not valid to activate both the voter override neg and voter override pos at the same time.
  [28] RX_REE_TXPOST_DIAG_12 rw — Voter override enable : Setting this bit to a 1'b1 will allow only the voter override pos and voter override neg bits in this register to control the voter in the peaking amp. Note : This function is intended to be for diagnostic and verification purposes only. Note : Both the voter override neg and voter override pos bits in this register must be set to 1'b0 when this bit is initially set to 1'b1 when enabling this function.
  [21:16] RX_REE_TXPOST_DIAG_5_0 ro — Current peaking amp integrator accumulator: Current value of the tap integrator accumulator, without the unused sign bit.
  [13:8] RX_REE_TXPOST_COVRD1_13_8 rw — Peaking amp code override value mode 3: Value that will override the peaking amp code when in standard mode 3 when the peaking amp code override enable bit in the REE TX post cursor diagnostics register (!) on page 270 is active.
  [5:0] RX_REE_TXPOST_COVRD1_5_0 rw — Peaking amp code override value mode 2: Value that will override the peaking amp code when in standard mode 2 when the peaking amp code override enable bit in the REE TX post cursor diagnostics register (!) on page 270 is active.
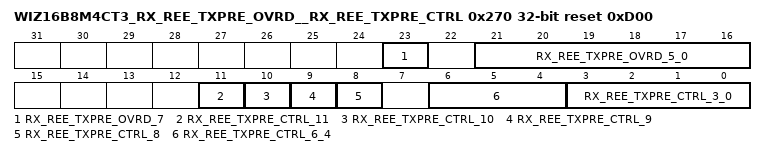
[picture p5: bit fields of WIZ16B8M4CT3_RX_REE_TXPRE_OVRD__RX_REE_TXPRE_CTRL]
0x270 WIZ16B8M4CT3_RX_REE_TXPRE_OVRD__RX_REE_TXPRE_CTRL reset 0xD00
  [23] RX_REE_TXPRE_OVRD_7 — Tap override enable: Setting this bit to a 1'b1 will enable the tap override field in this register to override the tap integrator accumulator functions. Note: This function is unused in the TX pre-cursor control.
  [21:16] RX_REE_TXPRE_OVRD_5_0 — Tap override value: When the tap override enable bit in this register is active, the value in this field will override the integrator accumulator value, as well as the input to the binary to thermometer encoder. Note: This function is unused in the TX pre-cursor control.
  [11] RX_REE_TXPRE_CTRL_11 — Tap coefficient combinational logic zero crossing enable: 1'b0: Zero crossing combinational logic input not enabled. 1'b1: Zero crossing combinational logic input enabled.
  [10] RX_REE_TXPRE_CTRL_10 — Tap coefficient combinational logic non zero crossing enable: 1'b0: non zero crossing combinational logic input not enabled. 1'b1: non zero crossing combinational logic input enabled.
  [9] RX_REE_TXPRE_CTRL_9 — Tap coefficient combinational logic bit 0 only enable: 1'b0: All enabled combinational logic input modules will be used. 1'b1: Only the enabled combinational logic input modules associated with bit 0 will be used.
  [8] RX_REE_TXPRE_CTRL_8 — Receiver DFE tap coefficient disable: This bit disables the rxda_dfe_tap_coef output signal. 1'b0 : rxda_dfe_tap_coef output enabled. 1'b1 : rxda_dfe_tap_coef output disabled (all 0s). Note: This function is unused in the TX pre-cursor control.
  [6:4] RX_REE_TXPRE_CTRL_6_4 — Tap integrator accumulator scaler value: Specifies the amount to scale the input to the tap integrator accumulator by. The following are the valid settings for this field: 3'b000: x1 3'b001 - 3'b111: Reserved Note: This function is unused in the TX pre-cursor control.
  [3:0] RX_REE_TXPRE_CTRL_3_0 — Tap sigma delta accumulator scaler value: Specifies the amount to scale the input to the tap sigma delta accumulator by. The following are the valid settings for this field: 4'b0000: x1 4'b0001: x2 4'b0010: x4 4'b0011: x8 4'b0100: x16 4'b0101: x 32 4'b0110: x 64 4'b0111: x128 4'b1000: x256 4'b1001: x512 4'b1010: x1024 4'b1011: x2048 4'b1100: x 4096 4'b1101 x 8192 4'b1110 x 16384 4'b1111 x 32768
